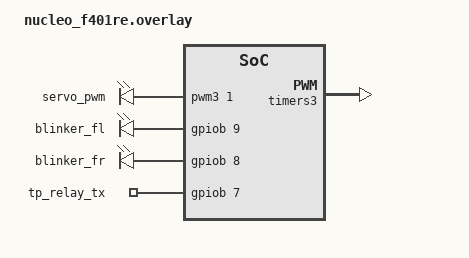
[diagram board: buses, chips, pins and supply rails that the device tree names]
/*
 * N2 steering zone (front). Applied after common/zephyr/dual_can.overlay,
 * which provides the CAN modules, CAN test points, DEG/ERR LEDs, TEST_BTN
 * and the watchdog.
 *
 *   SRV      PB4 (D5)   TIM3 CH1 (moved from Lab 2's PA6, now SPI1 MISO)
 *   FL       PB9 (D14)
 *   FR       PB8 (D15)
 *   RELAY_TX PB7        test point
 */
#include <zephyr/dt-bindings/pwm/stm32_pwm.h>

/ {
	aliases {
		servo-pwm = &servo_pwm;
		blinker-left = &blinker_fl;
		blinker-right = &blinker_fr;
		tp-relay-tx = &tp_relay_tx;
	};

	servo_outputs {
		compatible = "pwm-leds";

		servo_pwm: servo_pwm {
			pwms = <&pwm3 1 PWM_MSEC(20) PWM_POLARITY_NORMAL>;
		};
	};

	front_blinkers {
		compatible = "gpio-leds";

		blinker_fl: blinker_fl {
			gpios = <&gpiob 9 GPIO_ACTIVE_HIGH>;
		};
		blinker_fr: blinker_fr {
			gpios = <&gpiob 8 GPIO_ACTIVE_HIGH>;
		};
	};

	n2_test_points {
		compatible = "gpio-leds";

		tp_relay_tx: tp_relay_tx {
			gpios = <&gpiob 7 GPIO_ACTIVE_HIGH>;
		};
	};
};

&timers3 {
	/* 84 MHz / 28 = 3 MHz, so a 20 ms servo period is 60,000 counts */
	st,prescaler = <27>;
	status = "okay";

	pwm3: pwm {
		status = "okay";
		pinctrl-0 = <&tim3_ch1_pb4>;
		pinctrl-names = "default";
	};
};
